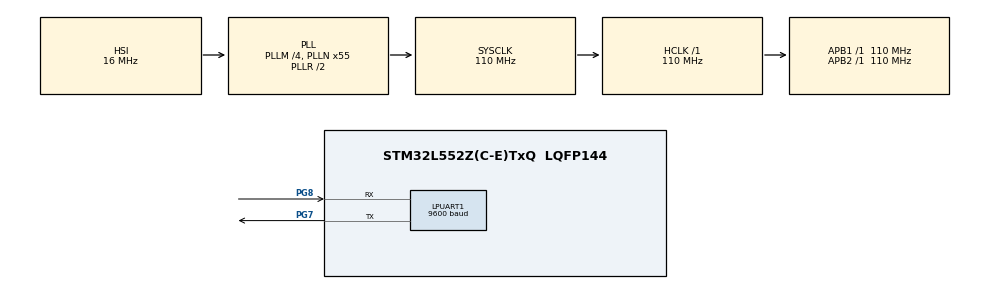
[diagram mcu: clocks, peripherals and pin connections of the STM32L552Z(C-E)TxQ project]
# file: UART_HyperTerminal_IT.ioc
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LPUART1.BaudRate=9600
LPUART1.DMADisableonRxErrorParam-Asynchronous=UART_ADVFEATURE_DMA_ENABLEONRXERROR
LPUART1.DataInvertParam-Asynchronous=UART_ADVFEATURE_DATAINV_DISABLE
LPUART1.MSBFirstParam-Asynchronous=UART_ADVFEATURE_MSBFIRST_DISABLE
LPUART1.Mode-Asynchronous=UART_MODE_TX_RX
LPUART1.OneBitSampling=UART_ONE_BIT_SAMPLE_DISABLE
LPUART1.OverrunDisableParam-Asynchronous=UART_ADVFEATURE_OVERRUN_ENABLE
LPUART1.Parity-Asynchronous=UART_PARITY_ODD
LPUART1.RXFIFOThreshold-Asynchronous=UART_RXFIFO_THRESHOLD_1_8
LPUART1.RxPinLevelInvertParam-Asynchronous=UART_ADVFEATURE_RXINV_DISABLE
LPUART1.StopBits-Asynchronous=UART_STOPBITS_1
LPUART1.SwapParam-Asynchronous=UART_ADVFEATURE_SWAP_DISABLE
LPUART1.TXFIFOThreshold-Asynchronous=UART_TXFIFO_THRESHOLD_1_8
LPUART1.TxPinLevelInvertParam-Asynchronous=UART_ADVFEATURE_TXINV_DISABLE
LPUART1.WordLength=UART_WORDLENGTH_8B
Mcu.Family=STM32L5
Mcu.Name=STM32L552Z(C-E)TxQ
Mcu.Package=LQFP144
NVIC.LPUART1_IRQn=true\:0\:0\:false\:false\:true\:true\:true\:true
NVIC.PriorityGroup=NVIC_PRIORITYGROUP_3
PG7.Mode=Asynchronous
PG7.Signal=LPUART1_TX
PG8.Mode=Asynchronous
PG8.Signal=LPUART1_RX
ProjectManager.HeapSize=0x200
ProjectManager.StackSize=0x400
ProjectManager.TargetToolchain=EWARM V8.32
RCC.ADCFreq_Value=48000000
RCC.AHBFreq_Value=110000000
RCC.APB1Freq_Value=110000000
RCC.APB1TimFreq_Value=110000000
RCC.APB2Freq_Value=110000000
RCC.APB2TimFreq_Value=110000000
RCC.CortexFreq_Value=110000000
RCC.DATA_CACHE_ENABLE=0
RCC.HCLKFreq_Value=110000000
RCC.HSE_VALUE=16000000
RCC.HSI48_VALUE=48000000
RCC.HSI_VALUE=16000000
RCC.INSTRUCTION_CACHE_ENABLE=0
RCC.LPUART1CLockSelectionVirtual=RCC_LPUART1CLKSOURCE_HSI
RCC.LSE_VALUE=32768
RCC.MSI_VALUE=4000000
RCC.PLLM=4
RCC.PLLN=55
RCC.PLLSAI1N=24
RCC.PLLSourceVirtual=RCC_PLLSOURCE_HSI
RCC.RTCClockSelection=RCC_RTCCLKSOURCE_LSE
RCC.SYSCLKFreq_VALUE=110000000
RCC.SYSCLKSource=RCC_SYSCLKSOURCE_PLLCLK
RCC.USBFreq_Value=48000000
RCC.VCOOutputFreq_Value=220000000
VP_ICACHE_VS_ICACHE.Mode=DirectMappedCache
VP_PWR_VS_DBSignals.Mode=DisableDeadBatterySignals
board=custom

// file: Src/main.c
/* USER CODE BEGIN Header */
/**
  ******************************************************************************
  * @file    UART/UART_HyperTerminal_IT/Src/main.c
  * @author  MCD Application Team
  * @brief   This sample code shows how to use UART HAL and LL APIs to transmit
  *          and receive a data buffer with a communication process based on IT;
  *          The communication is done with the Hyperterminal PC application;
  *          HAL driver is used to perform UART configuration,
  *          then TX/RX transfers procedures are based on LL APIs use
  ******************************************************************************
  * @attention
  *
  * Copyright (c) 2019 STMicroelectronics.
  * All rights reserved.
  *
  * This software is licensed under terms that can be found in the LICENSE file
  * in the root directory of this software component.
  * If no LICENSE file comes with this software, it is provided AS-IS.
  *
  ******************************************************************************
  */
/* USER CODE END Header */
#include "main.h"

UART_HandleTypeDef hlpuart1;

/* USER CODE BEGIN PV */

/* UART handler declaration */
UART_HandleTypeDef UartHandle;
__IO uint8_t  ubTxComplete = 0;
__IO uint8_t  ubRxComplete = 0;

/* Buffer used for transmission */
uint8_t aTxStartMessage[] = "\n\r ****UART-Hyperterminal communication based on IT (Mixed HAL/LL usage) ****\n\r Enter 10 characters using keyboard :\n\r";
__IO uint32_t uwTxIndex = 0;
uint8_t ubSizeToSend = sizeof(aTxStartMessage);
uint8_t aTxEndMessage[] = "\n\r Example Finished\n\r";

/* Buffer used for reception */
uint8_t aRxBuffer[RXBUFFERSIZE];
__IO uint32_t uwRxIndex = 0;

/* USER CODE END PV */

void SystemClock_Config(void);
static void MX_GPIO_Init(void);
static void MX_ICACHE_Init(void);
static void MX_LPUART1_UART_Init(void);

int main(void)
{
  /* USER CODE BEGIN 1 */
/* STM32L5xx HAL library initialization:
       - Systick timer is configured by default as source of time base, but user
         can eventually implement his proper time base source (a general purpose
         timer for example or other time source), keeping in mind that Time base
         duration should be kept 1ms since PPP_TIMEOUT_VALUEs are defined and
         handled in milliseconds basis.
       - Set NVIC Group Priority to 3
       - Low Level Initialization
     */
  /* USER CODE END 1 */

  /* MCU Configuration--------------------------------------------------------*/

  /* Reset of all peripherals, Initializes the Flash interface and the Systick. */
  HAL_Init();

  /* USER CODE BEGIN Init */
  /* Configure leds */
  BSP_LED_Init(LED1);
  BSP_LED_Init(LED2);
  BSP_LED_Init(LED3);

  /* USER CODE END Init */

  /* Configure the system clock */
  SystemClock_Config();

  /* Initialize all configured peripherals */
  MX_GPIO_Init();
  MX_ICACHE_Init();
  MX_LPUART1_UART_Init();
  /* USER CODE BEGIN 2 */

  /*## Configure UART peripheral for reception process (using LL) ##########*/
  /* Any data received will be stored "aRxBuffer" buffer : the number max of
     data received is RXBUFFERSIZE */
  /* Enable RXNE and Error interrupts */
  LL_USART_EnableIT_RXNE(LPUART1);
  LL_USART_EnableIT_ERROR(LPUART1);

  /*## Start the transmission process (using LL) *##########################*/
  /* While the UART in reception process, user can transmit data from
     "aTxStartMessage" buffer */
  /* Start USART transmission : Will initiate TXE interrupt after TDR register is empty */
  LL_USART_TransmitData8(LPUART1, aTxStartMessage[uwTxIndex++]);

  /* Enable TXE interrupt */
  LL_USART_EnableIT_TXE(LPUART1);

  /*## Wait for the end of the transfer ###################################*/
  /* USART IRQ handler is not anymore routed to HAL_UART_IRQHandler() function
     and is now based on LL API functions use.
     Therefore, use of HAL IT based services is no more possible. */
  /*  Once TX transfer is completed, LED1 will turn On.
      Then, when RX transfer is completed, LED2 will turn On. */
  while (ubTxComplete == 0)
  {
  }
  BSP_LED_On(LED1);

  while (ubRxComplete == 0)
  {
  }
  BSP_LED_On(LED2);

  /*## Send the received Buffer ###########################################*/
  /* Even if use of HAL IT based services is no more possible, use of HAL Polling based services
     (as Transmit in polling mode) is still possible. */
  if(HAL_UART_Transmit(&hlpuart1, (uint8_t*)aRxBuffer, RXBUFFERSIZE, 1000)!= HAL_OK)
  {
    /* Transfer error in transmission process */
    Error_Handler();
  }

  /*## Send the End Message ###############################################*/
  if(HAL_UART_Transmit(&hlpuart1, (uint8_t*)aTxEndMessage, TXENDMESSAGESIZE, 1000)!= HAL_OK)
  {
    /* Transfer error in transmission process */
    Error_Handler();
  }

  /* USER CODE END 2 */

  /* Infinite loop */
  while (1)
  {

  }
}

void SystemClock_Config(void)
{
  RCC_OscInitTypeDef RCC_OscInitStruct = {0};
  RCC_ClkInitTypeDef RCC_ClkInitStruct = {0};

  /** Configure the main internal regulator output voltage
  */
  if (HAL_PWREx_ControlVoltageScaling(PWR_REGULATOR_VOLTAGE_SCALE0) != HAL_OK)
  {
    Error_Handler();
  }

  /** Initializes the RCC Oscillators according to the specified parameters
  * in the RCC_OscInitTypeDef structure.
  */
  RCC_OscInitStruct.OscillatorType = RCC_OSCILLATORTYPE_HSI;
  RCC_OscInitStruct.HSIState = RCC_HSI_ON;
  RCC_OscInitStruct.HSICalibrationValue = RCC_HSICALIBRATION_DEFAULT;
  RCC_OscInitStruct.PLL.PLLState = RCC_PLL_ON;
  RCC_OscInitStruct.PLL.PLLSource = RCC_PLLSOURCE_HSI;
  RCC_OscInitStruct.PLL.PLLM = 4;
  RCC_OscInitStruct.PLL.PLLN = 55;
  RCC_OscInitStruct.PLL.PLLP = RCC_PLLP_DIV7;
  RCC_OscInitStruct.PLL.PLLQ = RCC_PLLQ_DIV2;
  RCC_OscInitStruct.PLL.PLLR = RCC_PLLR_DIV2;
  if (HAL_RCC_OscConfig(&RCC_OscInitStruct) != HAL_OK)
  {
    Error_Handler();
  }

  /** Initializes the CPU, AHB and APB buses clocks
  */
  RCC_ClkInitStruct.ClockType = RCC_CLOCKTYPE_HCLK|RCC_CLOCKTYPE_SYSCLK
                              |RCC_CLOCKTYPE_PCLK1|RCC_CLOCKTYPE_PCLK2;
  RCC_ClkInitStruct.SYSCLKSource = RCC_SYSCLKSOURCE_PLLCLK;
  RCC_ClkInitStruct.AHBCLKDivider = RCC_SYSCLK_DIV1;
  RCC_ClkInitStruct.APB1CLKDivider = RCC_HCLK_DIV1;
  RCC_ClkInitStruct.APB2CLKDivider = RCC_HCLK_DIV1;

  if (HAL_RCC_ClockConfig(&RCC_ClkInitStruct, FLASH_LATENCY_5) != HAL_OK)
  {
    Error_Handler();
  }
}

static void MX_ICACHE_Init(void)
{

  /** Enable instruction cache in 1-way (direct mapped cache)
  */
  if (HAL_ICACHE_ConfigAssociativityMode(ICACHE_1WAY) != HAL_OK)
  {
    Error_Handler();
  }
  if (HAL_ICACHE_Enable() != HAL_OK)
  {
    Error_Handler();
  }

}

static void MX_LPUART1_UART_Init(void)
{

  hlpuart1.Instance = LPUART1;
  hlpuart1.Init.BaudRate = 9600;
  hlpuart1.Init.WordLength = UART_WORDLENGTH_8B;
  hlpuart1.Init.StopBits = UART_STOPBITS_1;
  hlpuart1.Init.Parity = UART_PARITY_ODD;
  hlpuart1.Init.Mode = UART_MODE_TX_RX;
  hlpuart1.Init.HwFlowCtl = UART_HWCONTROL_NONE;
  hlpuart1.Init.OneBitSampling = UART_ONE_BIT_SAMPLE_DISABLE;
  hlpuart1.Init.ClockPrescaler = UART_PRESCALER_DIV1;
  hlpuart1.AdvancedInit.AdvFeatureInit = UART_ADVFEATURE_NO_INIT;
  hlpuart1.FifoMode = UART_FIFOMODE_DISABLE;
  if (HAL_UART_Init(&hlpuart1) != HAL_OK)
  {
    Error_Handler();
  }
  if (HAL_UARTEx_SetTxFifoThreshold(&hlpuart1, UART_TXFIFO_THRESHOLD_1_8) != HAL_OK)
  {
    Error_Handler();
  }
  if (HAL_UARTEx_SetRxFifoThreshold(&hlpuart1, UART_RXFIFO_THRESHOLD_1_8) != HAL_OK)
  {
    Error_Handler();
  }
  if (HAL_UARTEx_DisableFifoMode(&hlpuart1) != HAL_OK)
  {
    Error_Handler();
  }

}

static void MX_GPIO_Init(void)
{

  /* GPIO Ports Clock Enable */
  __HAL_RCC_GPIOG_CLK_ENABLE();
  HAL_PWREx_EnableVddIO2();

}

/* USER CODE BEGIN 4 */

/**
  * @brief  Rx Transfer completed callback
  * @note   This example shows a simple way to report end of IT Rx transfer, and
  *         you can add your own implementation.
  * @retval None
  */
void UART_CharReception_Callback(void)
{
  /* Read Received character. RXNE flag is cleared by reading of RDR register */
  aRxBuffer[uwRxIndex++] = LL_USART_ReceiveData8(LPUART1);

  /* Check if reception is completed (expected nb of bytes has been received) */
  if (uwRxIndex == RXBUFFERSIZE)
  {
    /* Set Reception complete boolean to 1 */
    ubRxComplete = 1;
  }
}

/**
  * @brief  Function called for achieving next TX Byte sending
  * @retval None
  */
void UART_TXEmpty_Callback(void)
{
  if(uwTxIndex == (ubSizeToSend - 1))
  {
    /* Disable TXE interrupt */
    LL_USART_DisableIT_TXE(LPUART1);

    /* Enable TC interrupt */
    LL_USART_EnableIT_TC(LPUART1);
  }

  /* Fill TDR with a new char */
  LL_USART_TransmitData8(LPUART1, aTxStartMessage[uwTxIndex++]);
}

/**
  * @brief  Function called at completion of last byte transmission
  * @retval None
  */
void UART_CharTransmitComplete_Callback(void)
{
  if(uwTxIndex == sizeof(aTxStartMessage))
  {
    uwTxIndex = 0;

    /* Disable TC interrupt */
    LL_USART_DisableIT_TC(LPUART1);

    /* Set Tx complete boolean to 1 */
    ubTxComplete = 1;
  }
}

/**
  * @brief  UART error callbacks
  * @note   This example shows a simple way to report transfer error, and you can
  *         add your own implementation.
  * @retval None
  */
void UART_Error_Callback(void)
{
  __IO uint32_t isr_reg;

  /* Disable USARTx_IRQn */
  NVIC_DisableIRQ(LPUART1_IRQn);

  /* Error handling example :
    - Read USART ISR register to identify flag that leads to IT raising
    - Perform corresponding error handling treatment according to flag
  */
  isr_reg = LL_USART_ReadReg(LPUART1, ISR);
  if (isr_reg & LL_USART_ISR_NE)
  {
    /* Turn LED3 on: Transfer error in reception/transmission process */
    BSP_LED_On(LED3);
  }
  else
  {
    /* Turn LED3 on: Transfer error in reception/transmission process */
    BSP_LED_On(LED3);
  }
}

/* USER CODE END 4 */

void Error_Handler(void)
{
  /* USER CODE BEGIN Error_Handler_Debug */
  /* User can add his own implementation to report the HAL error return state */
  /* Toggle LED3 for error */
  while(1)
  {
    BSP_LED_Toggle(LED3);
    HAL_Delay(1000);
  }
  /* USER CODE END Error_Handler_Debug */
}

#ifdef  USE_FULL_ASSERT
/**
  * @brief  Reports the name of the source file and the source line number
  *         where the assert_param error has occurred.
  * @param  file: pointer to the source file name
  * @param  line: assert_param error line source number
  * @retval None
  */
void assert_failed(uint8_t *file, uint32_t line)
{
  /* USER CODE BEGIN 6 */
  /* User can add his own implementation to report the file name and line number,
     ex: printf("Wrong parameters value: file %s on line %d\r\n", file, line) */
  /* Infinite loop */
  while (1)
  {}
  /* USER CODE END 6 */
}
#endif /* USE_FULL_ASSERT */
